# ET6801 register map
Vendor: ETMCU Inc.; File version: v0.0.1
CPU: CM7 r2p1, little endian, MPU, FPU, I-cache, D-cache, ITCM, DTCM, 4 interrupt priority bits
Registers are 32-bit, read-write, reset 0x0 unless marked. A register's access mark holds for its fields unless they carry their own. Offsets are from the block's base; [hi:lo] are bit positions; {n}, {i} and the like mark numbered series; 'fields as' and 'values as' point back to an identical list.

## EMIF1 — Provide an overview of the purpose and functionality of the peripheral: smc_cfg_ids
Base 0x40606000
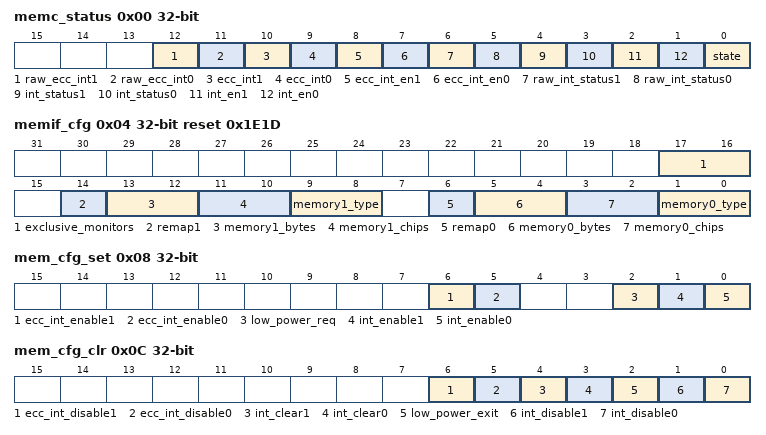
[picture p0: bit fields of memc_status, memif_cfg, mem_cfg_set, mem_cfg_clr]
0x00 memc_status ro (reset mask 0xFFF80000) — Describe the details of the register: memc_status
  [12] raw_ecc_int1 — Raw status of the ecc_int1 interrupt signal.
  [11] raw_ecc_int0 — Raw status of the ecc_int0 interrupt signal.
  [10] ecc_int1 — Status of the ecc_int1 interrupt signal after ANDing with its enable bit, ecc_int_en1.
  [9] ecc_int0 — Status of the ecc_int0 interrupt signal after ANDing with its enable bit, ecc_int_en0.
  [8] ecc_int_en1 — Interrupt enable status for ecc_int1: 0 = Interrupt is disabled so ecc_int1 is LOW. 1 = Interrupt is enabled.
  [7] ecc_int_en0 — Interrupt enable status for ecc_int0: 0 = Interrupt is disabled so ecc_int0 is LOW. 1 = Interrupt is enabled
  [6] raw_int_status1 — Raw status of the smc_int1 interrupt signal.
  [5] raw_int_status0 — Raw status of the smc_int0 interrupt signal.
  [4] int_status1 — Status of the smc_int1 interrupt signal after ANDing with its enable bit, int_en1.
  [3] int_status0 — Status of the smc_int0 interrupt signal after ANDing with its enable bit, int_en0.
  [2] int_en1 — Interrupt enable status for smc_int1: 0 = Interrupt is disabled so smc_int1 is LOW. 1 = Interrupt is enabled.
  [1] int_en0 — Interrupt enable status for smc_int0: 0 = Interrupt is disabled so smc_int0 is LOW. 1 = Interrupt is enabled.
  [0] state — Operating state of the SMC: 0 = SMC is in the Ready state 1 = SMC is in the Low-power state.
0x04 memif_cfg ro reset 0x1E1D (reset mask 0xFEFEC000) — Describe the details of the register: memif_cfg
  [17:16] exclusive_monitors — Returns the number of exclusive access monitor resources that are implemented in the SMC. b00 = 0 monitors b01 = 1 monitor b10 = 2 monitors b11 = 4 monitors. See Exclusive accesses on SMC databook page 2-12.
  [14] remap1 — Returns the value of the remap_1 input. See Miscellaneous signals on SMC databook page B-3.
  [13:12] memory1_bytes — Returns the maximum width of the SMC memory data bus for interface 1: b00 = 8 bits b01 = 16 bits b10 = 32 bits b11 = reserved.
  [11:10] memory1_chips — Returns the number of different chip selects that the memory interface 1 supports: b00 = 1 chip b01 = 2 chips b10 = 3 chips b11 = 4 chips.
  [9:8] memory1_type — Returns the memory interface 1 type: b00 = Configuration does not include this memory interface b01 = SRAM non-multiplexed b10 = NAND b11 = SRAM multiplexed. If b00, the remaining bit slices for memory interface 1 are always read as 0.
  [6] remap0 — Returns the value of the remap_0 input. See Miscellaneous signals on SMC databook page B-3.
  [5:4] memory0_bytes — Returns the maximum width of the SMC memory data bus for interface 0: b00 = 8 bits b01 = 16 bits b10 = 32 bits b11 = reserved.
  [3:2] memory0_chips — Returns the number of different chip selects that the memory interface 0 supports: b00 = 1 chip b01 = 2 chips b10 = 3 chips b11 = 4 chips.
  [1:0] memory0_type — Returns the memory interface 0 type: b00 = reserved b01 = SRAM non-multiplexed b10 = NAND b11 = SRAM multiplexed.
0x08 mem_cfg_set (reset mask 0xE6000000) — Describe the details of the register: mem_cfg_set
  [6] ecc_int_enable1 — 0 = No effect 1 = Enables the ecc_int1 interrupt. SMC sets the ecc_int_en1 bit to 1 in the memc_status Register, see Memory Controller Status Register on SMC databook page 3-8.
  [5] ecc_int_enable0 — 0 = No effect 1 = Enables the ecc_int0 interrupt. SMC sets the ecc_int_en0 bit to 1 in the memc_status Register, see Memory Controller Status Register on SMC databook page 3-8.
  [2] low_power_req — 0 = No effect 1 = Requests the SMC to enter Low-power state when it next becomes idle.
  [1] int_enable1 — 0 = No effect 1 = Enables the smc_int1 interrupt. SMC sets the int_en1 bit to 1 in the memc_status Register, see Memory Controller Status Register on SMC databook page 3-8.
  [0] int_enable0 — 0 = No effect 1 = Enables the smc_int0 interrupt. SMC sets the int_en0 bit to 1 in the memc_status Register, see Memory Controller Status Register on SMC databook page 3-8.
0x0C mem_cfg_clr (reset mask 0xFE000000) — Describe the details of the register: mem_cfg_clr
  [6] ecc_int_disable1 — 0 = No effect 1 = Disables the ecc_int1 interrupt. SMC sets the ecc_int_en1 bit to 0 in the memc_status Register, see Memory Controller Status Register on SMC databook page 3-8
  [5] ecc_int_disable0 — 0 = No effect 1 = Disables the ecc_int0 interrupt. SMC sets the ecc_int_en0 bit to 0 in the memc_status Register, see Memory Controller Status Register on SMC databook page 3-8
  [4] int_clear1 — 0 = No effect 1 = Clear SMC Interrupt 1, as an alternative to an AXI read.
  [3] int_clear0 — 0 = No effect 1 = Clear SMC Interrupt 0, as an alternative to an AXI read.
  [2] low_power_exit — 0 = No effect 1 = Request the SMC to exit Low-power state.
  [1] int_disable1 — 0 = No effect 1 = Disables the smc_int1 interrupt. SMC sets the int_en1 bit to 0 in the memc_status Register, see Memory Controller Status Register on SMC databook page 3-8
  [0] int_disable0 — 0 = No effect 1 = Disables the smc_int0 interrupt. SMC sets the int_en0 bit to 0 in the memc_status Register, see Memory Controller Status Register on SMC databook page 3-8
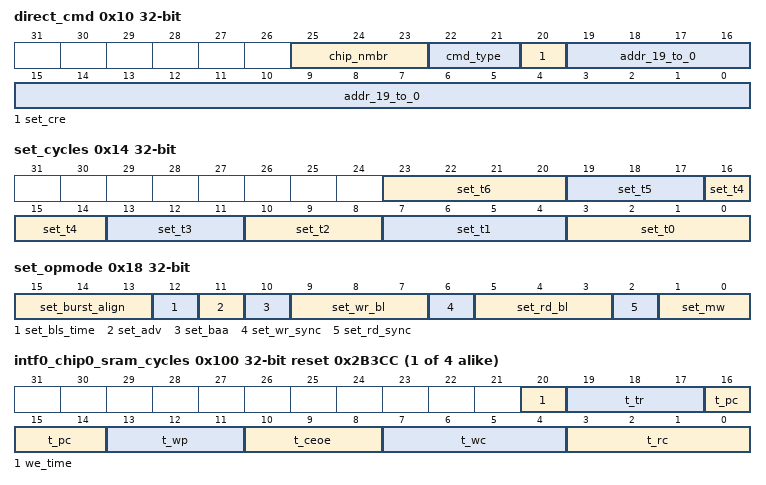
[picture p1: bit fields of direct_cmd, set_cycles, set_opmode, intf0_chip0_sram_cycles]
0x10 direct_cmd (reset mask 0xFFFFFFC0) — Describe the details of the register: direct_cmd
  [25:23] chip_nmbr — Selects chip configuration register bank to update, and enables chip mode register access depending on cmd_type. The encoding is: b000-b011 = Chip selects 1-4 on memory interface 0 b100-b111 = Chip selects 1-4 on memory interface 1.
  [22:21] cmd_type — Selects the command type: b00 = UpdateRegs and AXI b01 = ModeReg b10 = UpdateRegs b11 = ModeReg and UpdateRegs.
  [20] set_cre — Maps to the configuration register enable signal, cre, when a ModeReg command is issued. The encoding is: 0 = cre is LOW 1 = cre is HIGH when ModeReg write occurs.
  [19:0] addr_19_to_0 — When cmd_type = UpdateRegs and AXI then: • bits [15:0] are used to match wdata[15:0] • bits [19:16] are reserved. Write as zero. When cmd_type = ModeReg or ModeReg and UpdateRegs, these bits map to the external memory address bits [19:0]. When cmd_type = UpdateRegs, these bits are reserved. Write as zero.
0x14 set_cycles (reset mask 0xFFFFFF00) — Describe the details of the register: set_cycles
  [23:20] set_t6 — Contains the value to be written to either the: • we_time bit of the SRAM Cycles Register on SMC databook page 3-20a • t_rr field of the NAND Cycles Register on SMC databook page 3-21.
  [19:17] set_t5 — Contains the value to be written to either the:• t_tr field of the SRAM Cycles Register on SMC databook page 3-20• t_ar field of the NAND Cycles Register on SMC databook page 3-21.
  [16:14] set_t4 — Contains the value to be written to either the: • t_pc field of the SRAM Cycles Register on SMC databook page 3-20 • t_clr field of the NAND Cycles Register on SMC databook page 3-21.
  [13:11] set_t3 — Contains the value to be written to the t_wp field in either the: • SRAM Cycles Register on SMC databook page 3-20b • NAND Cycles Register on SMC databook page 3-21.
  [10:8] set_t2 — Contains the value to be written to either the: • t_ceoe field of the SRAM Cycles Register on SMC databook page 3-20c • t_rea field of the NAND Cycles Register on SMC databook page 3-21.
  [7:4] set_t1 — Contains the value to be written to the t_wc field in either the: • SRAM Cycles Register on SMC databook page 3-20 • NAND Cycles Register on SMC databook page 3-21.
  [3:0] set_t0 — Contains the value to be written to the t_rc field in either the: • SRAM Cycles Register on SMC databook page 3-20 • NAND Cycles Register on SMC databook page 3-21.
0x18 set_opmode (reset mask 0xFFFF0000) — Describe the details of the register: set_opmode
  [15:13] set_burst_align — Contains the value to be written to the specific SRAM chip opmode Register burst_align field. When you configure the SMC to perform synchronous transfersa, these bits control if memory bursts are split on memory burst boundaries: b000 = bursts can cross any address boundary b001 = burst split on memory burst boundary, that is, 32 beats for continuous b010 = burst split on 64 beat boundary b011 = burst split on 128 beat boundary b100 = burst split on 256 beat boundary b101-b111 = reserved. For a NAND memory interface these bits are reserved, and written as zero.
  [12] set_bls_time — Contains the value to be written to the specific SRAM chip opmode Register byte lane strobe (bls) bit. This bit affects the assertion of the byte lane strobe outputs. 0 = bls timing equals chip select timing. This is the default setting. 1 = bls timing equals we_n timing. This setting is used for eight memories that have no bls_n inputs. In this case, the bls_n output of the SMC is connected to the we_n memory input. For a NAND memory interface this bit is reserved, and written as zero.
  [11] set_adv — Contains the value to be written to the specific SRAM chip opmode Register address valid (adv) bit. The memory uses the address advance signal adv_n when set. For a NAND memory interface this bit is reserved, and written as zero.
  [10] set_baa — Contains the value to be written to the specific SRAM chip opmode Register burst address advance (baa) bit. The memory uses the baa_n signal when set. For a NAND memory interface this bit is reserved, and written as zero.
  [9:7] set_wr_bl — Contains the value to be written to the specific SRAM chip opmode Register wr_bl field. Encodes the memory burst length: b000 = 1 beat b001 = 4 beats b010 = 8 beats b011 = 16 beats b100 = 32 beats b101 = continuous b110-b111 = reserved. For a NAND memory interface these bits are reserved, and written as zero.
  [6] set_wr_sync — Contains the value to be written to the specific SRAM chip opmode Register wr_sync bit. The memory writes are synchronous when set. For a NAND memory interface this bit is reserved, and written as zero.
  [5:3] set_rd_bl — Contains the value to be written to the specific SRAM chip opmode Register rd_bl field. Encodes the memory burst length: b000 = 1 beat b001 = 4 beats b010 = 8 beats b011 = 16 beats b100 = 32 beats b101 = continuous b110-b111 = reserved. For a NAND memory interface these bits are reserved, and written as zero.
  [2] set_rd_sync — Contains the value to be written to the specific SRAM chip opmode Register rd_sync bit. Memory in sync mode when set.For a NAND memory interface this bit is reserved, and written as zero.
  [1:0] set_mw — Contains the value to be written to the specific chip opmode Register memory width (mw) field. Encodes the memory data bus width: b00 = 8 bitsb b01 = 16 bitsb b10 = 32 bits b11 = reserved. You can program this to the configured width, or half that width. See Memory Interface Configuration Register on SMC databook page 3-9.
0x20 refresh_0 (reset mask 0xF0000000) — Describe the details of the register: refresh_0
  [3:0] ref_period0 — Sets the number of consecutive memory burstsa that the SMC permits, on memory interface 0, before it deasserts the chip select. The options are:b0000 = disables the insertion of idle cycles between consecutive burstsb0001 = an idle cycle occurs after each burstb0010 = an idle cycle occurs after 2 consecutive burstsb0011 = an idle cycle occurs after 3 consecutive burstsb0100 = an idle cycle occurs after 4 consecutive bursts...b1111 = an idle cycle occurs after 15 consecutive bursts.
0x24 refresh_1 (reset mask 0xF0000000) — Describe the details of the register: refresh_1
  [3:0] ref_period1 — Sets the number of consecutive memory burstsa that the SMC permits, on memory interface 1, before it deasserts the chip select. The options are:b0000 = disables the insertion of idle cycles between consecutive burstsb0001 = an idle cycle occurs after each burstb0010 = an idle cycle occurs after 2 consecutive burstsb0011 = an idle cycle occurs after 3 consecutive burstsb0100 = an idle cycle occurs after 4 consecutive bursts...b1111 = an idle cycle occurs after 15 consecutive bursts.
{0x100+0x20*i} intf0_chip{i}_sram_cycles ro reset 0x2B3CC (reset mask 0xFFFFF800) (i=0..3) — Describe the details of the register: intf0_chip{i}_sram_cycles
  [20] we_time — For asynchronous multiplexed transfers this bit returns when the SMC asserts we_n:0 = SMC asserts we_n two mclk cycles after asserting cs_n. See Figure 2-17 on SMC databook page 2-29.1 = SMC asserts we_n and cs_n together.
  [19:17] t_tr — Returns the turnaround time. Minimum permitted value = 1.
  [16:14] t_pc — Returns the page cycle time. Minimum permitted value = 1.
  [13:11] t_wp — Returns the we_n assertion delay. Minimum permitted value = 1.
  [10:8] t_ceoe — Returns the oe_n assertion delay. Minimum permitted value = 1.
  [7:4] t_wc — Returns the write cycle time. Minimum permitted value = 2.
  [3:0] t_rc — Returns the read cycle time. Minimum permitted value = 2.
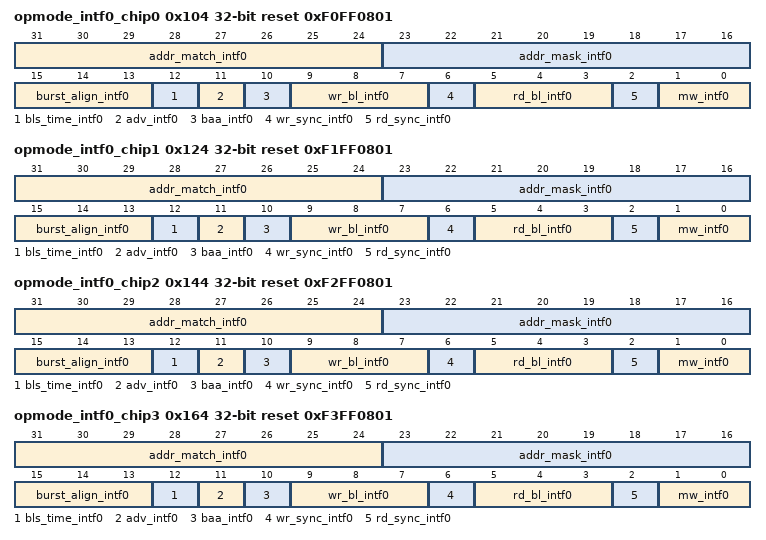
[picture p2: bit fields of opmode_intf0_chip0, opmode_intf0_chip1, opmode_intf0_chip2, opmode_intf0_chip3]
0x104 opmode_intf0_chip0 ro reset 0xF0FF0801 — Describe the details of the register: opmode_intf0_chip0
  [31:24] addr_match_intf0 — Returns the value of the addr_match_intf0_chip0[7:0] tie-off. This is the comparison value for address bits [31:24] to determine the chip that is selected.
  [23:16] addr_mask_intf0 — Returns the value of the addr_mask_intf0_chip0[7:0] tie-off. This is the mask for address bits[31:24]. A logic 1 indicates the bit is used for comparison.
  [15:13] burst_align_intf0 — When you program the SMC to perform synchronous transfersa, these bits return the memory burst operating mode:b000 = bursts can cross any address boundary. This is the default setting.b001 = burst split on memory burst boundary, that is, 32 beats for continuous.b010 = burst split on 64 beat boundary.b011 = burst split on 128 beat boundary.b100 = burst split on 256 beat boundary.b101-b111 = reserved.The reset value is b000.For a NAND memory interface these bits are reserved.
  [12] bls_time_intf0 — Returns the byte lane strobe operating mode for an SRAM memory interface:0 = bls timing equals chip select timing. This is the default setting.1 = bls timing equals we_n timing.For a NAND memory interface this bit is reserved.
  [11] adv_intf0 — Returns the address advance signal operating mode for an SRAM memory interface:0 = SMC ties adv_n HIGH. This is the default setting.1 = SMC sets adv_n LOW at the start of a transfer.For a NAND memory interface this bit is reserved.
  [10] baa_intf0 — Returns the burst address advance signal operating mode for an SRAM memory interface:0 = SMC ties baa_n HIGH. This is the default setting.1 = SMC sets baa_n LOW.For a NAND memory interface this bit is reserved.
  [9:7] wr_bl_intf0 — Returns the memory burst length for writes on an SRAM memory interface:b000 = 1 beat. This is the default setting.b001 = 4 beatsb010 = 8 beatsb011 = 16 beatsb100 = 32 beatsb101 = continuousb110-b111 = reserved.For a NAND memory interface these bits are reserved.
  [6] wr_sync_intf0 — Returns the write operating mode for an SRAM memory interface:0 = SMC performs asynchronous writes. This is the default setting.1 = SMC performs synchronous writes.For a NAND memory interface this bit is reserved.
  [5:3] rd_bl_intf0 — Returns the memory burst length for reads on an SRAM memory interface:b000 = 1 beat. This is the default setting.b001 = 4 beatsb010 = 8 beatsb011 = 16 beatsb100 = 32 beatsb101 = continuousb110-b111 = reserved.For a NAND memory interface these bits are reserved.
  [2] rd_sync_intf0 — Returns the read operating mode for an SRAM memory interface:0 = SMC performs asynchronous reads. This is the default setting.1 = SMC performs synchronous reads.For a NAND memory interface this bit is reserved.
  [1:0] mw_intf0 — Returns the SMC memory data bus width:b00 = 8 bitsb01 = 16 bitsb10 = 32 bitsb11 = reserved.You can use the sram_mw__intf0[1:0] or nand_mw__intf0 tie-offs to set the memory width for chip select 0, memory interface _intf0, to enable booting from that chip. The reset value of memory width for all other chip selects is the configured width.
0x124 opmode_intf0_chip1 ro reset 0xF1FF0801 — Describe the details of the register: opmode_intf0_chip1
  [31:24] addr_match_intf0 — Returns the value of the addr_match_intf0_chip1[7:0] tie-off. This is the comparison value for address bits [31:24] to determine the chip that is selected.
  [23:16] addr_mask_intf0 — Returns the value of the addr_mask_intf0_chip1[7:0] tie-off. This is the mask for address bits[31:24]. A logic 1 indicates the bit is used for comparison.
  [15:13] burst_align_intf0 — When you program the SMC to perform synchronous transfersa, these bits return the memory burst operating mode:b000 = bursts can cross any address boundary. This is the default setting.b001 = burst split on memory burst boundary, that is, 32 beats for continuous.b010 = burst split on 64 beat boundary.b011 = burst split on 128 beat boundary.b100 = burst split on 256 beat boundary.b101-b111 = reserved.The reset value is b000.For a NAND memory interface these bits are reserved.
  [12] bls_time_intf0 — Returns the byte lane strobe operating mode for an SRAM memory interface:0 = bls timing equals chip select timing. This is the default setting.1 = bls timing equals we_n timing.For a NAND memory interface this bit is reserved.
  [11] adv_intf0 — Returns the address advance signal operating mode for an SRAM memory interface:0 = SMC ties adv_n HIGH. This is the default setting.1 = SMC sets adv_n LOW at the start of a transfer.For a NAND memory interface this bit is reserved.
  [10] baa_intf0 — Returns the burst address advance signal operating mode for an SRAM memory interface:0 = SMC ties baa_n HIGH. This is the default setting.1 = SMC sets baa_n LOW.For a NAND memory interface this bit is reserved.
  [9:7] wr_bl_intf0 — Returns the memory burst length for writes on an SRAM memory interface:b000 = 1 beat. This is the default setting.b001 = 4 beatsb010 = 8 beatsb011 = 16 beatsb100 = 32 beatsb101 = continuousb110-b111 = reserved.For a NAND memory interface these bits are reserved.
  [6] wr_sync_intf0 — Returns the write operating mode for an SRAM memory interface:0 = SMC performs asynchronous writes. This is the default setting.1 = SMC performs synchronous writes.For a NAND memory interface this bit is reserved.
  [5:3] rd_bl_intf0 — Returns the memory burst length for reads on an SRAM memory interface:b000 = 1 beat. This is the default setting.b001 = 4 beatsb010 = 8 beatsb011 = 16 beatsb100 = 32 beatsb101 = continuousb110-b111 = reserved.For a NAND memory interface these bits are reserved.
  [2] rd_sync_intf0 — Returns the read operating mode for an SRAM memory interface:0 = SMC performs asynchronous reads. This is the default setting.1 = SMC performs synchronous reads.For a NAND memory interface this bit is reserved.
  [1:0] mw_intf0 — Returns the SMC memory data bus width:b00 = 8 bitsb01 = 16 bitsb10 = 32 bitsb11 = reserved.You can use the sram_mw__intf0[1:0] or nand_mw__intf0 tie-offs to set the memory width for chip select 0, memory interface _intf0, to enable booting from that chip. The reset value of memory width for all other chip selects is the configured width.
0x144 opmode_intf0_chip2 ro reset 0xF2FF0801 — Describe the details of the register: opmode_intf0_chip2
  [31:24] addr_match_intf0 — Returns the value of the addr_match_intf0_chip2[7:0] tie-off. This is the comparison value for address bits [31:24] to determine the chip that is selected.
  [23:16] addr_mask_intf0 — Returns the value of the addr_mask_intf0_chip2[7:0] tie-off. This is the mask for address bits[31:24]. A logic 1 indicates the bit is used for comparison.
  [15:13] burst_align_intf0 — When you program the SMC to perform synchronous transfersa, these bits return the memory burst operating mode:b000 = bursts can cross any address boundary. This is the default setting.b001 = burst split on memory burst boundary, that is, 32 beats for continuous.b010 = burst split on 64 beat boundary.b011 = burst split on 128 beat boundary.b100 = burst split on 256 beat boundary.b101-b111 = reserved.The reset value is b000.For a NAND memory interface these bits are reserved.
  [12] bls_time_intf0 — Returns the byte lane strobe operating mode for an SRAM memory interface:0 = bls timing equals chip select timing. This is the default setting.1 = bls timing equals we_n timing.For a NAND memory interface this bit is reserved.
  [11] adv_intf0 — Returns the address advance signal operating mode for an SRAM memory interface:0 = SMC ties adv_n HIGH. This is the default setting.1 = SMC sets adv_n LOW at the start of a transfer.For a NAND memory interface this bit is reserved.
  [10] baa_intf0 — Returns the burst address advance signal operating mode for an SRAM memory interface:0 = SMC ties baa_n HIGH. This is the default setting.1 = SMC sets baa_n LOW.For a NAND memory interface this bit is reserved.
  [9:7] wr_bl_intf0 — Returns the memory burst length for writes on an SRAM memory interface:b000 = 1 beat. This is the default setting.b001 = 4 beatsb010 = 8 beatsb011 = 16 beatsb100 = 32 beatsb101 = continuousb110-b111 = reserved.For a NAND memory interface these bits are reserved.
  [6] wr_sync_intf0 — Returns the write operating mode for an SRAM memory interface:0 = SMC performs asynchronous writes. This is the default setting.1 = SMC performs synchronous writes.For a NAND memory interface this bit is reserved.
  [5:3] rd_bl_intf0 — Returns the memory burst length for reads on an SRAM memory interface:b000 = 1 beat. This is the default setting.b001 = 4 beatsb010 = 8 beatsb011 = 16 beatsb100 = 32 beatsb101 = continuousb110-b111 = reserved.For a NAND memory interface these bits are reserved.
  [2] rd_sync_intf0 — Returns the read operating mode for an SRAM memory interface:0 = SMC performs asynchronous reads. This is the default setting.1 = SMC performs synchronous reads.For a NAND memory interface this bit is reserved.
  [1:0] mw_intf0 — Returns the SMC memory data bus width:b00 = 8 bitsb01 = 16 bitsb10 = 32 bitsb11 = reserved.You can use the sram_mw__intf0[1:0] or nand_mw__intf0 tie-offs to set the memory width for chip select 0, memory interface _intf0, to enable booting from that chip. The reset value of memory width for all other chip selects is the configured width.
0x164 opmode_intf0_chip3 ro reset 0xF3FF0801 — Describe the details of the register: opmode_intf0_chip3
  [31:24] addr_match_intf0 — Returns the value of the addr_match_intf0_chip3[7:0] tie-off. This is the comparison value for address bits [31:24] to determine the chip that is selected.
  [23:16] addr_mask_intf0 — Returns the value of the addr_mask_intf0_chip3[7:0] tie-off. This is the mask for address bits[31:24]. A logic 1 indicates the bit is used for comparison.
  [15:13] burst_align_intf0 — When you program the SMC to perform synchronous transfersa, these bits return the memory burst operating mode:b000 = bursts can cross any address boundary. This is the default setting.b001 = burst split on memory burst boundary, that is, 32 beats for continuous.b010 = burst split on 64 beat boundary.b011 = burst split on 128 beat boundary.b100 = burst split on 256 beat boundary.b101-b111 = reserved.The reset value is b000.For a NAND memory interface these bits are reserved.
  [12] bls_time_intf0 — Returns the byte lane strobe operating mode for an SRAM memory interface:0 = bls timing equals chip select timing. This is the default setting.1 = bls timing equals we_n timing.For a NAND memory interface this bit is reserved.
  [11] adv_intf0 — Returns the address advance signal operating mode for an SRAM memory interface:0 = SMC ties adv_n HIGH. This is the default setting.1 = SMC sets adv_n LOW at the start of a transfer.For a NAND memory interface this bit is reserved.
  [10] baa_intf0 — Returns the burst address advance signal operating mode for an SRAM memory interface:0 = SMC ties baa_n HIGH. This is the default setting.1 = SMC sets baa_n LOW.For a NAND memory interface this bit is reserved.
  [9:7] wr_bl_intf0 — Returns the memory burst length for writes on an SRAM memory interface:b000 = 1 beat. This is the default setting.b001 = 4 beatsb010 = 8 beatsb011 = 16 beatsb100 = 32 beatsb101 = continuousb110-b111 = reserved.For a NAND memory interface these bits are reserved.
  [6] wr_sync_intf0 — Returns the write operating mode for an SRAM memory interface:0 = SMC performs asynchronous writes. This is the default setting.1 = SMC performs synchronous writes.For a NAND memory interface this bit is reserved.
  [5:3] rd_bl_intf0 — Returns the memory burst length for reads on an SRAM memory interface:b000 = 1 beat. This is the default setting.b001 = 4 beatsb010 = 8 beatsb011 = 16 beatsb100 = 32 beatsb101 = continuousb110-b111 = reserved.For a NAND memory interface these bits are reserved.
  [2] rd_sync_intf0 — Returns the read operating mode for an SRAM memory interface:0 = SMC performs asynchronous reads. This is the default setting.1 = SMC performs synchronous reads.For a NAND memory interface this bit is reserved.
  [1:0] mw_intf0 — Returns the SMC memory data bus width:b00 = 8 bitsb01 = 16 bitsb10 = 32 bitsb11 = reserved.You can use the sram_mw__intf0[1:0] or nand_mw__intf0 tie-offs to set the memory width for chip select 0, memory interface _intf0, to enable booting from that chip. The reset value of memory width for all other chip selects is the configured width.
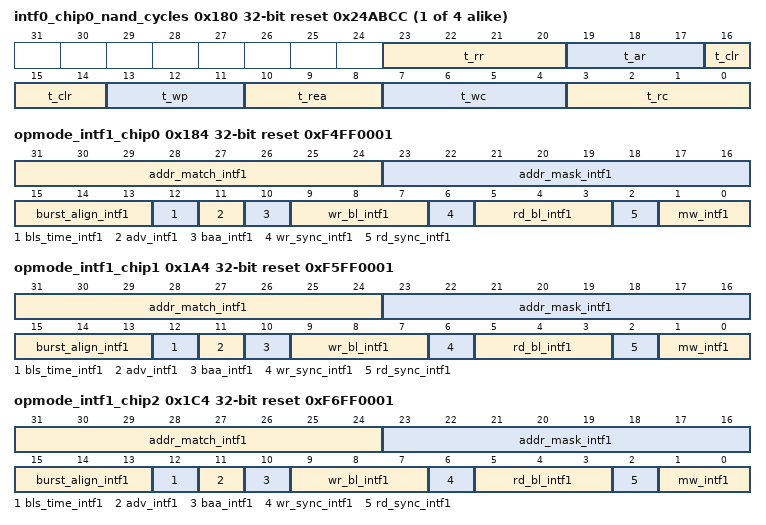
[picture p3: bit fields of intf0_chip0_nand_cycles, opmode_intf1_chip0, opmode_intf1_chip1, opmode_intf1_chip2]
{0x180+0x20*i} intf0_chip{i}_nand_cycles ro reset 0x24ABCC (reset mask 0xFFFFFF00) (i=0..3) — Describe the details of the register: intf0_chip{i}_nand_cycles
  [23:20] t_rr — Returns the busy to re_n time. Minimum permitted value = 0.
  [19:17] t_ar — Returns the ID read time. Minimum permitted value = 0.
  [16:14] t_clr — Returns the status read time. Minimum permitted value = 0.
  [13:11] t_wp — Returns the we_n deassertion delay. Minimum permitted value = 1.
  [10:8] t_rea — Returns the re_n assertion delay. Minimum permitted value = 1.
  [7:4] t_wc — Returns the write cycle time. Minimum permitted value = 2.
  [3:0] t_rc — Returns the read cycle time. Minimum permitted value = 2.
0x184 opmode_intf1_chip0 ro reset 0xF4FF0001 — Describe the details of the register: opmode_intf1_chip0
  [31:24] addr_match_intf1 — Returns the value of the addr_match_intf1_chip0[7:0] tie-off. This is the comparison value for address bits [31:24] to determine the chip that is selected.
  [23:16] addr_mask_intf1 — Returns the value of the addr_mask_intf1_chip0[7:0] tie-off. This is the mask for address bits[31:24]. A logic 1 indicates the bit is used for comparison.
  [15:13] burst_align_intf1 — When you program the SMC to perform synchronous transfersa, these bits return the memory burst operating mode:b000 = bursts can cross any address boundary. This is the default setting.b001 = burst split on memory burst boundary, that is, 32 beats for continuous.b010 = burst split on 64 beat boundary.b011 = burst split on 128 beat boundary.b100 = burst split on 256 beat boundary.b101-b111 = reserved.The reset value is b000.For a NAND memory interface these bits are reserved.
  [12] bls_time_intf1 — Returns the byte lane strobe operating mode for an SRAM memory interface:0 = bls timing equals chip select timing. This is the default setting.1 = bls timing equals we_n timing.For a NAND memory interface this bit is reserved.
  [11] adv_intf1 — Returns the address advance signal operating mode for an SRAM memory interface:0 = SMC ties adv_n HIGH. This is the default setting.1 = SMC sets adv_n LOW at the start of a transfer.For a NAND memory interface this bit is reserved.
  [10] baa_intf1 — Returns the burst address advance signal operating mode for an SRAM memory interface:0 = SMC ties baa_n HIGH. This is the default setting.1 = SMC sets baa_n LOW.For a NAND memory interface this bit is reserved.
  [9:7] wr_bl_intf1 — Returns the memory burst length for writes on an SRAM memory interface:b000 = 1 beat. This is the default setting.b001 = 4 beatsb010 = 8 beatsb011 = 16 beatsb100 = 32 beatsb101 = continuousb110-b111 = reserved.For a NAND memory interface these bits are reserved.
  [6] wr_sync_intf1 — Returns the write operating mode for an SRAM memory interface:0 = SMC performs asynchronous writes. This is the default setting.1 = SMC performs synchronous writes.For a NAND memory interface this bit is reserved.
  [5:3] rd_bl_intf1 — Returns the memory burst length for reads on an SRAM memory interface:b000 = 1 beat. This is the default setting.b001 = 4 beatsb010 = 8 beatsb011 = 16 beatsb100 = 32 beatsb101 = continuousb110-b111 = reserved.For a NAND memory interface these bits are reserved.
  [2] rd_sync_intf1 — Returns the read operating mode for an SRAM memory interface:0 = SMC performs asynchronous reads. This is the default setting.1 = SMC performs synchronous reads.For a NAND memory interface this bit is reserved.
  [1:0] mw_intf1 — Returns the SMC memory data bus width:b00 = 8 bitsb01 = 16 bitsb10 = 32 bitsb11 = reserved.You can use the sram_mw__intf1[1:0] or nand_mw__intf1 tie-offs to set the memory width for chip select 0, memory interface _intf1, to enable booting from that chip. The reset value of memory width for all other chip selects is the configured width.
0x1A4 opmode_intf1_chip1 ro reset 0xF5FF0001 — Describe the details of the register: opmode_intf1_chip1
  [31:24] addr_match_intf1 — Returns the value of the addr_match_intf1_chip1[7:0] tie-off. This is the comparison value for address bits [31:24] to determine the chip that is selected.
  [23:16] addr_mask_intf1 — Returns the value of the addr_mask_intf1_chip1[7:0] tie-off. This is the mask for address bits[31:24]. A logic 1 indicates the bit is used for comparison.
  [15:13] burst_align_intf1 — When you program the SMC to perform synchronous transfersa, these bits return the memory burst operating mode:b000 = bursts can cross any address boundary. This is the default setting.b001 = burst split on memory burst boundary, that is, 32 beats for continuous.b010 = burst split on 64 beat boundary.b011 = burst split on 128 beat boundary.b100 = burst split on 256 beat boundary.b101-b111 = reserved.The reset value is b000.For a NAND memory interface these bits are reserved.
  [12] bls_time_intf1 — Returns the byte lane strobe operating mode for an SRAM memory interface:0 = bls timing equals chip select timing. This is the default setting.1 = bls timing equals we_n timing.For a NAND memory interface this bit is reserved.
  [11] adv_intf1 — Returns the address advance signal operating mode for an SRAM memory interface:0 = SMC ties adv_n HIGH. This is the default setting.1 = SMC sets adv_n LOW at the start of a transfer.For a NAND memory interface this bit is reserved.
  [10] baa_intf1 — Returns the burst address advance signal operating mode for an SRAM memory interface:0 = SMC ties baa_n HIGH. This is the default setting.1 = SMC sets baa_n LOW.For a NAND memory interface this bit is reserved.
  [9:7] wr_bl_intf1 — Returns the memory burst length for writes on an SRAM memory interface:b000 = 1 beat. This is the default setting.b001 = 4 beatsb010 = 8 beatsb011 = 16 beatsb100 = 32 beatsb101 = continuousb110-b111 = reserved.For a NAND memory interface these bits are reserved.
  [6] wr_sync_intf1 — Returns the write operating mode for an SRAM memory interface:0 = SMC performs asynchronous writes. This is the default setting.1 = SMC performs synchronous writes.For a NAND memory interface this bit is reserved.
  [5:3] rd_bl_intf1 — Returns the memory burst length for reads on an SRAM memory interface:b000 = 1 beat. This is the default setting.b001 = 4 beatsb010 = 8 beatsb011 = 16 beatsb100 = 32 beatsb101 = continuousb110-b111 = reserved.For a NAND memory interface these bits are reserved.
  [2] rd_sync_intf1 — Returns the read operating mode for an SRAM memory interface:0 = SMC performs asynchronous reads. This is the default setting.1 = SMC performs synchronous reads.For a NAND memory interface this bit is reserved.
  [1:0] mw_intf1 — Returns the SMC memory data bus width:b00 = 8 bitsb01 = 16 bitsb10 = 32 bitsb11 = reserved.You can use the sram_mw__intf1[1:0] or nand_mw__intf1 tie-offs to set the memory width for chip select 0, memory interface _intf1, to enable booting from that chip. The reset value of memory width for all other chip selects is the configured width.
0x1C4 opmode_intf1_chip2 ro reset 0xF6FF0001 — Describe the details of the register: opmode_intf1_chip2
  [31:24] addr_match_intf1 — Returns the value of the addr_match_intf1_chip2[7:0] tie-off. This is the comparison value for address bits [31:24] to determine the chip that is selected.
  [23:16] addr_mask_intf1 — Returns the value of the addr_mask_intf1_chip2[7:0] tie-off. This is the mask for address bits[31:24]. A logic 1 indicates the bit is used for comparison.
  [15:13] burst_align_intf1 — When you program the SMC to perform synchronous transfersa, these bits return the memory burst operating mode:b000 = bursts can cross any address boundary. This is the default setting.b001 = burst split on memory burst boundary, that is, 32 beats for continuous.b010 = burst split on 64 beat boundary.b011 = burst split on 128 beat boundary.b100 = burst split on 256 beat boundary.b101-b111 = reserved.The reset value is b000.For a NAND memory interface these bits are reserved.
  [12] bls_time_intf1 — Returns the byte lane strobe operating mode for an SRAM memory interface:0 = bls timing equals chip select timing. This is the default setting.1 = bls timing equals we_n timing.For a NAND memory interface this bit is reserved.
  [11] adv_intf1 — Returns the address advance signal operating mode for an SRAM memory interface:0 = SMC ties adv_n HIGH. This is the default setting.1 = SMC sets adv_n LOW at the start of a transfer.For a NAND memory interface this bit is reserved.
  [10] baa_intf1 — Returns the burst address advance signal operating mode for an SRAM memory interface:0 = SMC ties baa_n HIGH. This is the default setting.1 = SMC sets baa_n LOW.For a NAND memory interface this bit is reserved.
  [9:7] wr_bl_intf1 — Returns the memory burst length for writes on an SRAM memory interface:b000 = 1 beat. This is the default setting.b001 = 4 beatsb010 = 8 beatsb011 = 16 beatsb100 = 32 beatsb101 = continuousb110-b111 = reserved.For a NAND memory interface these bits are reserved.
  [6] wr_sync_intf1 — Returns the write operating mode for an SRAM memory interface:0 = SMC performs asynchronous writes. This is the default setting.1 = SMC performs synchronous writes.For a NAND memory interface this bit is reserved.
  [5:3] rd_bl_intf1 — Returns the memory burst length for reads on an SRAM memory interface:b000 = 1 beat. This is the default setting.b001 = 4 beatsb010 = 8 beatsb011 = 16 beatsb100 = 32 beatsb101 = continuousb110-b111 = reserved.For a NAND memory interface these bits are reserved.
  [2] rd_sync_intf1 — Returns the read operating mode for an SRAM memory interface:0 = SMC performs asynchronous reads. This is the default setting.1 = SMC performs synchronous reads.For a NAND memory interface this bit is reserved.
  [1:0] mw_intf1 — Returns the SMC memory data bus width:b00 = 8 bitsb01 = 16 bitsb10 = 32 bitsb11 = reserved.You can use the sram_mw__intf1[1:0] or nand_mw__intf1 tie-offs to set the memory width for chip select 0, memory interface _intf1, to enable booting from that chip. The reset value of memory width for all other chip selects is the configured width.
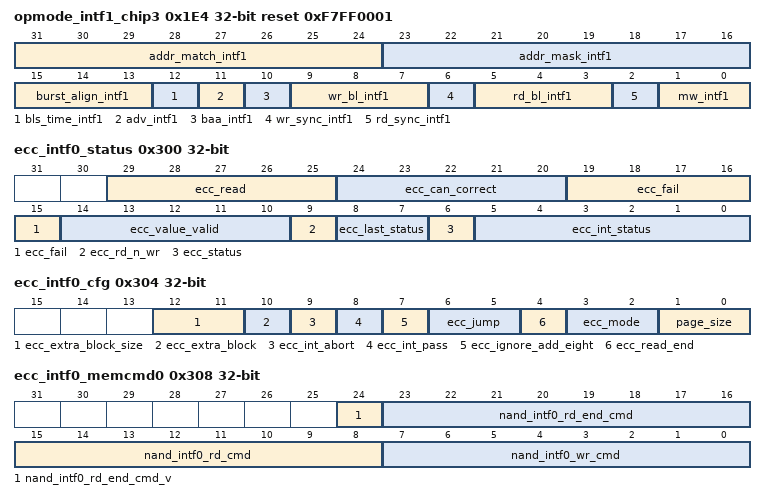
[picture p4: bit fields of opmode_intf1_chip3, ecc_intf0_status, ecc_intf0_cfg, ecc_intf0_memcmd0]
0x1E4 opmode_intf1_chip3 ro reset 0xF7FF0001 — Describe the details of the register: opmode_intf1_chip3
  [31:24] addr_match_intf1 — Returns the value of the addr_match_intf1_chip3[7:0] tie-off. This is the comparison value for address bits [31:24] to determine the chip that is selected.
  [23:16] addr_mask_intf1 — Returns the value of the addr_mask_intf1_chip3[7:0] tie-off. This is the mask for address bits[31:24]. A logic 1 indicates the bit is used for comparison.
  [15:13] burst_align_intf1 — When you program the SMC to perform synchronous transfersa, these bits return the memory burst operating mode:b000 = bursts can cross any address boundary. This is the default setting.b001 = burst split on memory burst boundary, that is, 32 beats for continuous.b010 = burst split on 64 beat boundary.b011 = burst split on 128 beat boundary.b100 = burst split on 256 beat boundary.b101-b111 = reserved.The reset value is b000.For a NAND memory interface these bits are reserved.
  [12] bls_time_intf1 — Returns the byte lane strobe operating mode for an SRAM memory interface:0 = bls timing equals chip select timing. This is the default setting.1 = bls timing equals we_n timing.For a NAND memory interface this bit is reserved.
  [11] adv_intf1 — Returns the address advance signal operating mode for an SRAM memory interface:0 = SMC ties adv_n HIGH. This is the default setting.1 = SMC sets adv_n LOW at the start of a transfer.For a NAND memory interface this bit is reserved.
  [10] baa_intf1 — Returns the burst address advance signal operating mode for an SRAM memory interface:0 = SMC ties baa_n HIGH. This is the default setting.1 = SMC sets baa_n LOW.For a NAND memory interface this bit is reserved.
  [9:7] wr_bl_intf1 — Returns the memory burst length for writes on an SRAM memory interface:b000 = 1 beat. This is the default setting.b001 = 4 beatsb010 = 8 beatsb011 = 16 beatsb100 = 32 beatsb101 = continuousb110-b111 = reserved.For a NAND memory interface these bits are reserved.
  [6] wr_sync_intf1 — Returns the write operating mode for an SRAM memory interface:0 = SMC performs asynchronous writes. This is the default setting.1 = SMC performs synchronous writes.For a NAND memory interface this bit is reserved.
  [5:3] rd_bl_intf1 — Returns the memory burst length for reads on an SRAM memory interface:b000 = 1 beat. This is the default setting.b001 = 4 beatsb010 = 8 beatsb011 = 16 beatsb100 = 32 beatsb101 = continuousb110-b111 = reserved.For a NAND memory interface these bits are reserved.
  [2] rd_sync_intf1 — Returns the read operating mode for an SRAM memory interface:0 = SMC performs asynchronous reads. This is the default setting.1 = SMC performs synchronous reads.For a NAND memory interface this bit is reserved.
  [1:0] mw_intf1 — Returns the SMC memory data bus width:b00 = 8 bitsb01 = 16 bitsb10 = 32 bitsb11 = reserved.You can use the sram_mw__intf1[1:0] or nand_mw__intf1 tie-offs to set the memory width for chip select 0, memory interface _intf1, to enable booting from that chip. The reset value of memory width for all other chip selects is the configured width.
0x200 user_status ro (reset mask 0xFF000000) — Describe the details of the register: user_status
  [7:0] user_status — This value returns the state of the user_status[7:0] inputs
0x204 user_config (reset mask 0xFF000000) — Describe the details of the register: user_config
  [7:0] user_config — This value sets the state of the user_config[7:0] outputs
0x300 ecc_intf0_status (reset mask 0xFFFFFFFC) — Describe the details of the register: ecc_intf0_status
  [29:25] ecc_read — Read flags for ECC blocks. Indicates whether the stored ECC value for each block has been read from memory0 = not read1 = read.
  [24:20] ecc_can_correct — Correctable flag for each ECC block. Indicates if the detected error is correctablea:0 = not correctable1 = correctable.See Table 2-33 on SMC databook page 2-48 for the decoding information of the ecc_can_correct flag and ecc_fail flag.
  [19:15] ecc_fail — Pass, fail flag for each ECC block:0 = pass1 = fail.See Table 2-33 on SMC databook page 2-48 for the decoding information of the ecc_can_correct flag and ecc_fail flag.
  [14:10] ecc_value_valid — Valid flag for each ECC block.
  [9] ecc_rd_n_wr — 0 = write1 = read.
  [8:7] ecc_last_status — b00 = Completed successfullyb01 = Unaligned address, or out-of-rangeb10 = Data stop after incomplete blockb11 = Data stopped but values not read/written because of ecc_jump value.Note The ecc_last_status bit is only updated at the completion of an ECC calculation.
  [6] ecc_status — Provides the status of the ECC block:0 = idle1 = busy.
  [5:0] ecc_int_status — The interrupts are:【5】Abort.【4】Extra block (if used).【3】Block 3.【2】Block 2.【1】Block 1.【0】Block 0.NoteTo clear an interrupt, write a 1 to the appropriate bit.
0x304 ecc_intf0_cfg (reset mask 0xFFF80000) — Describe the details of the register: ecc_intf0_cfg
  [12:11] ecc_extra_block_size — The size of the extra block in memory after the last 512-byte block:b00 = 4 bytesb01 = 8 bytesb10 = 16 bytesb11 = 32 bytes.Note These bits are only present if you configure the SMC to use the ECC Extra Block Enable option. See the CoreLink SMC-35x AXI Static Memory Controller Series Supplement to AMBA Designer (FD001) User Guide for information about enabling this option.
  [10] ecc_extra_block — If configured, this enables a small block for extra information after the last 512 bytes block in the page.Note These bits are only present if the ECC Extra Block Enable option is configured.
  [9] ecc_int_abort — Interrupt on ECC abort.
  [8] ecc_int_pass — Interrupt when a correct ECC value is read from memory.
  [7] ecc_ignore_add_eight — This bit is used to indicate if A8 is output with the address, required to find the aligned start of blocks:0 = A8 is output1 = A8 is not output.See Secondary mode addressing on SMC databook page 2-45.
  [6:5] ecc_jump — Indicates that the memory supports column change address commands:b00 = no jumping, reads and writes only occur at end of pageb01 = jump using column change commandsb10 = jump using full commandb11 = reserved.
  [4] ecc_read_end — Indicates when ECC values are read from memory:0 = the ECC value for a block must be read immediately after the block. Data access must stop on a 512 byte boundary.1 = ECC values for all blocks are read at the end of the page.
  [3:2] ecc_mode — This specifies the mode of the ECC block:b00 = bypassed.b01 = ECC values are calculated and made available on the APB interface, but they are not read from or written to memory.b10 = ECC values and calculated and read/written to memory. For a read, the ECC value is checked and the result of the check is made available on the APB interface.b11 = reserved.
  [1:0] page_size — The number of 512 byte blocks in a page:b00 = No 512 byte blocks. Reserved if an ecc_extra_block is not configured, or if an ecc_extra_block is configured but is not enabled.b01 = One 512 byte block.b10 = Two 512 byte blocks.b11 = Four 512 byte blocks.
0x308 ecc_intf0_memcmd0 (reset mask 0xFFFFFF80) — Describe the details of the register: ecc_intf0_memcmd0
  [24] nand_intf0_rd_end_cmd_v — Use end command
  [23:16] nand_intf0_rd_end_cmd — The NAND command to indicate the end of a read (0x30)
  [15:8] nand_intf0_rd_cmd — The NAND command to initiate a read (0x00)
  [7:0] nand_intf0_wr_cmd — The NAND command to initiate a write (0x80)
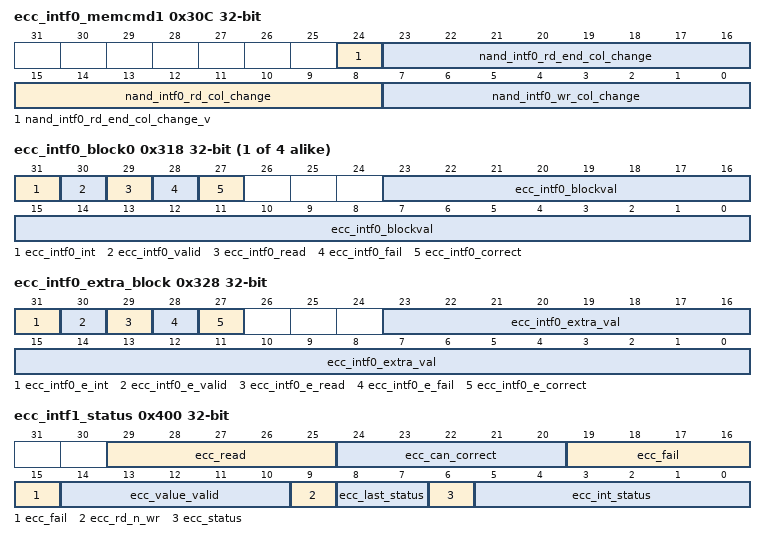
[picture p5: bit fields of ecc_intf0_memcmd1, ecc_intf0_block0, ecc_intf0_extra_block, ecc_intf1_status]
0x30C ecc_intf0_memcmd1 (reset mask 0xFFFFFF80) — Describe the details of the register: ecc_intf0_memcmd1
  [24] nand_intf0_rd_end_col_change_v — Use end command
  [23:16] nand_intf0_rd_end_col_change — The NAND command to indicate the end of a column change read (0xE0)
  [15:8] nand_intf0_rd_col_change — The NAND command (0x05) that is either:• a command to initiate a column change read• a spare bits pointer command.
  [7:0] nand_intf0_wr_col_change — The NAND command to initiate a column change write (0x85)
0x310 ecc_intf0_addr0 ro — Describe the details of the register: ecc_intf0_addr0
  [31:0] ecc_intf0_add_low — Address bits 31 to 0 for memory interface _intf0
0x314 ecc_intf0_addr1 ro (reset mask 0xFFFFFF00) — Describe the details of the register: ecc_intf0_addr1
  [23:0] ecc_intf0_add_high — Address bits [55:32] for memory interface _intf0
{0x318+4i} ecc_intf0_block{i} (reset mask 0xFFFFFF1F) (i=0..3) — Describe the details of the register: ecc_intf0_block{i}
  [31] ecc_intf0_int — Interrupt flag for block {i}. To clear this bit, write any value to the register.
  [30] ecc_intf0_valid — Indicates if the ECC value for block {i} is valid.
  [29] ecc_intf0_read — Indicates if the ECC value for block {i} has been read from memory.
  [28] ecc_intf0_fail — Indicates if the ECC value for block {i} has failed.See Table 2-33 on SMC databook page 2-48 for the decoding information of the ecc_can_correct flag and ecc_fail flag.
  [27] ecc_intf0_correct — Indicates if block {i} is correctable.See Table 2-33 on SMC databook page 2-48 for the decoding information of the ecc_can_correct flag and ecc_fail flag.
  [23:0] ecc_intf0_blockval — ECC value of check result for block {i}.
0x328 ecc_intf0_extra_block (reset mask 0xFFFFFF1F) — Describe the details of the register: ecc_intf0_extra_block
  [31] ecc_intf0_e_int — Interrupt flag for the extra block. To clear this bit, write any value to the register.
  [30] ecc_intf0_e_valid — Indicates if the ECC value for extra block is valid.
  [29] ecc_intf0_e_read — Indicates if the ECC value for extra block has been read from memory.
  [28] ecc_intf0_e_fail — Indicates if the ECC value for extra block has failed.
  [27] ecc_intf0_e_correct — Indicates if the extra block is correctable.
  [23:0] ecc_intf0_extra_val — ECC value of check result for the extra block.
0x400 ecc_intf1_status (reset mask 0xFFFFFFFC) — Describe the details of the register: ecc_intf1_status
  fields as ecc_intf0_status
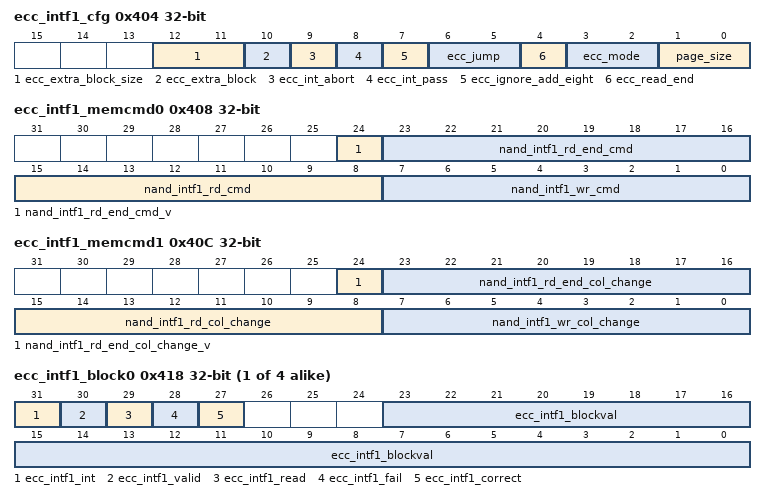
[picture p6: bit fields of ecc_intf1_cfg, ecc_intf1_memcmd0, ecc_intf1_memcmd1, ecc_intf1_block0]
0x404 ecc_intf1_cfg (reset mask 0xFFF80000) — Describe the details of the register: ecc_intf1_cfg
  fields as ecc_intf0_cfg
0x408 ecc_intf1_memcmd0 (reset mask 0xFFFFFF80) — Describe the details of the register: ecc_intf1_memcmd0
  [24] nand_intf1_rd_end_cmd_v — Use end command
  [23:16] nand_intf1_rd_end_cmd — The NAND command to indicate the end of a read (0x30)
  [15:8] nand_intf1_rd_cmd — The NAND command to initiate a read (0x00)
  [7:0] nand_intf1_wr_cmd — The NAND command to initiate a write (0x80)
0x40C ecc_intf1_memcmd1 (reset mask 0xFFFFFF80) — Describe the details of the register: ecc_intf1_memcmd1
  [24] nand_intf1_rd_end_col_change_v — Use end command
  [23:16] nand_intf1_rd_end_col_change — The NAND command to indicate the end of a column change read (0xE0)
  [15:8] nand_intf1_rd_col_change — The NAND command (0x05) that is either:• a command to initiate a column change read• a spare bits pointer command.
  [7:0] nand_intf1_wr_col_change — The NAND command to initiate a column change write (0x85)
0x410 ecc_intf1_addr0 ro — Describe the details of the register: ecc_intf1_addr0
  [31:0] ecc_intf1_add_low — Address bits 31 to 0 for memory interface _intf1
0x414 ecc_intf1_addr1 ro (reset mask 0xFFFFFF00) — Describe the details of the register: ecc_intf1_addr1
  [23:0] ecc_intf1_add_high — Address bits [55:32] for memory interface _intf1
{0x418+4i} ecc_intf1_block{i} (reset mask 0xFFFFFF1F) (i=0..3) — Describe the details of the register: ecc_intf1_block{i}
  [31] ecc_intf1_int — Interrupt flag for block {i}. To clear this bit, write any value to the register.
  [30] ecc_intf1_valid — Indicates if the ECC value for block {i} is valid.
  [29] ecc_intf1_read — Indicates if the ECC value for block {i} has been read from memory.
  [28] ecc_intf1_fail — Indicates if the ECC value for block {i} has failed.See Table 2-33 on SMC databook page 2-48 for the decoding information of the ecc_can_correct flag and ecc_fail flag.
  [27] ecc_intf1_correct — Indicates if block {i} is correctable.See Table 2-33 on SMC databook page 2-48 for the decoding information of the ecc_can_correct flag and ecc_fail flag.
  [23:0] ecc_intf1_blockval — ECC value of check result for block {i}.
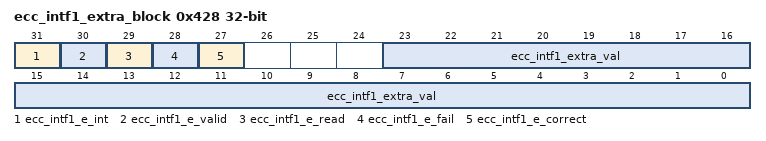
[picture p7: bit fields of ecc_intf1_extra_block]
0x428 ecc_intf1_extra_block (reset mask 0xFFFFFF1F) — Describe the details of the register: ecc_intf1_extra_block
  [31] ecc_intf1_e_int — Interrupt flag for the extra block. To clear this bit, write any value to the register.
  [30] ecc_intf1_e_valid — Indicates if the ECC value for extra block is valid.
  [29] ecc_intf1_e_read — Indicates if the ECC value for extra block has been read from memory.
  [28] ecc_intf1_e_fail — Indicates if the ECC value for extra block has failed.
  [27] ecc_intf1_e_correct — Indicates if the extra block is correctable.
  [23:0] ecc_intf1_extra_val — ECC value of check result for the extra block.
